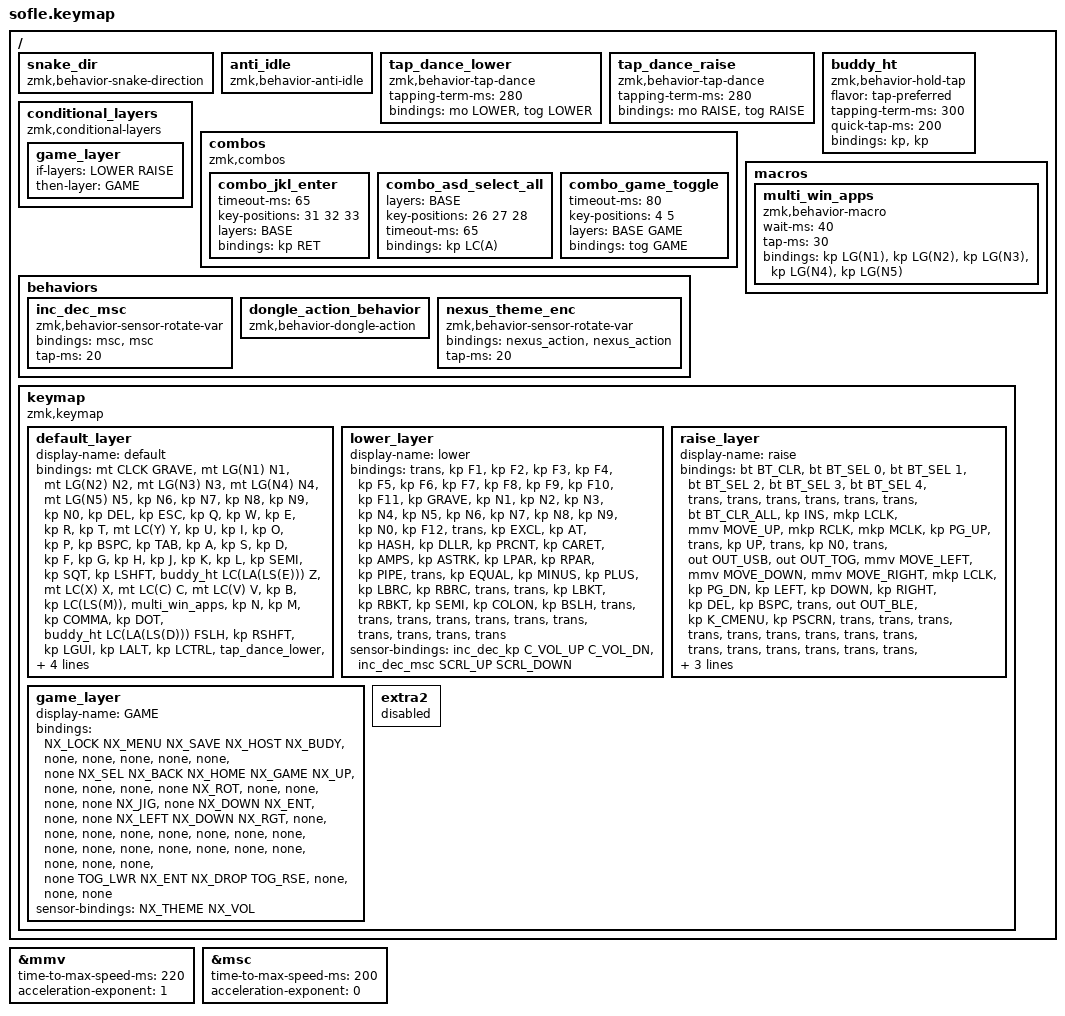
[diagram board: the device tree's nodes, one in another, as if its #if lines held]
/*
 * Copyright (c) 2020 The ZMK Contributors
 *
 * SPDX-License-Identifier: MIT
 */
#include <behaviors.dtsi>
#include <dt-bindings/zmk/keys.h>
#include <dt-bindings/zmk/bt.h>
#include <dt-bindings/zmk/rgb.h>
#include <dt-bindings/zmk/ext_power.h>
#include <dt-bindings/zmk/outputs.h>

/* --------------------------------------------------------------------------
 * Pointing defaults
 * -------------------------------------------------------------------------- */
#define ZMK_POINTING_DEFAULT_MOVE_VAL 1200
#define ZMK_POINTING_DEFAULT_SCRL_VAL 65
/* NEW: Replaced mouse.h with pointing.h for latest ZMK main branch */
#include <dt-bindings/zmk/pointing.h>

#define BASE 0
#define LOWER 1
#define RAISE 2
#define GAME 3

/ {
    /* ----------------------------------------------------------------------
     * Custom behaviors
     * ---------------------------------------------------------------------- */
    // ---------- SNAKE DIRECTION BEHAVIOR ----------
    snake_dir: snake_dir {
        compatible = "zmk,behavior-snake-direction";
        #binding-cells = <1>;
    };

    // ---------- ANTI-IDLE (HUMANIZED MOUSE JIGGLER) TOGGLE ----------
    anti_idle: anti_idle {
        compatible = "zmk,behavior-anti-idle";
        #binding-cells = <0>;
    };

    // ---------- TAP-DANCE FOR CUSTOM LAYER BEHAVIOR ----------
    tap_dance_lower: tap_dance_lower {
        compatible = "zmk,behavior-tap-dance";
        #binding-cells = <0>;
        tapping-term-ms = <280>;   // double-tap speed
        bindings = <&mo LOWER>, <&tog LOWER>;
    };

    tap_dance_raise: tap_dance_raise {
        compatible = "zmk,behavior-tap-dance";
        #binding-cells = <0>;
        tapping-term-ms = <280>;
        bindings = <&mo RAISE>, <&tog RAISE>;
    };

    // ---------- BUDDY ON HOLD: Z what's this?, / dictate ----------
    // Tap-preferred, not &mt's hold-preferred: only a real hold sends the
    // hotkey, so a fast roll like "/u" in a URL never starts Buddy talking.
    buddy_ht: buddy_ht {
        compatible = "zmk,behavior-hold-tap";
        #binding-cells = <2>;
        flavor = "tap-preferred";
        tapping-term-ms = <300>;
        quick-tap-ms = <200>;      // tap then hold = repeat the letter
        bindings = <&kp>, <&kp>;
    };

    /* Activate the GAME layer when LOWER and RAISE are both held. */
    conditional_layers {
        compatible = "zmk,conditional-layers";
        game_layer {
            if-layers = <LOWER RAISE>;
            then-layer = <GAME>;
        };
    };

    /* ----------------------------------------------------------------------
     * Combos
     * ---------------------------------------------------------------------- */
    combos {
        compatible = "zmk,combos";

        combo_jkl_enter {
            timeout-ms = <65>;          // Time window to press J+K+L together
            key-positions = <31 32 33>; // J, K, L positions in default_layer
            layers = <BASE>;            // Only active on BASE (default) layer
            bindings = <&kp RET>;       // Sends Enter
        };

        combo_asd_select_all {
            /* A + S + D on the left home row. */
            layers = <BASE>;
            key-positions = <26 27 28>;  // A, S, D 
            timeout-ms = <65>;
            bindings = <&kp LC(A)>;
        };

        combo_game_toggle {
            /*
             * 4 + 5 (left-hand number row) toggles the GAME layer, so you can
             * stay in it without holding LOWER+RAISE while you play.
             */
            timeout-ms = <80>;
            key-positions = <4 5>;  // number-row 4 + 5
            layers = <BASE GAME>;
            bindings = <&tog GAME>;
        };

    };

    /* ----------------------------------------------------------------------
     * Macros
     * ---------------------------------------------------------------------- */
    /* Launch or focus pinned Windows apps 1 through 5. */
    macros {
        multi_win_apps: multi_win_apps {
            compatible = "zmk,behavior-macro";
            #binding-cells = <0>;
            wait-ms = <40>;
            tap-ms  = <30>;
            bindings = <
                &kp LG(N1)
                &kp LG(N2)
                &kp LG(N3)
                &kp LG(N4)
                &kp LG(N5)
            >;
        };
    };

    behaviors {
        /* Scroll wheel behavior for the encoder sensor. */
        inc_dec_msc: inc_dec_msc {
            compatible = "zmk,behavior-sensor-rotate-var";
            #sensor-binding-cells = <2>;
            bindings = <&msc>, <&msc>;
            tap-ms = <20>;
        };

        // Dongle action toggle (snake <-> menu). Defined here so peripheral
        // builds compile; merges with the identical node in snake_adapter.overlay
        // on the dongle build.
        dongle_action_behavior: dongle_action_behavior {
            compatible = "zmk,behavior-dongle-action";
            #binding-cells = <0>;
        };
    };

    keymap {
        compatible = "zmk,keymap";

        default_layer {
            display-name = "default";
            /*
             * DEFAULT
             * ,-----------------------------------------------.   ,-----------------------------------------------.
             * | ` Caps | Win1 | Win2 | Win3 | Win4 | Win5     |   |  6   |  7   |  8   |  9   |  0   | Del      |
             * | Esc    |  Q   |  W   |  E   |  R   |  T       |   | C-Y  |  U   |  I   |  O   |  P   | Bksp     |
             * | Tab    |  A   |  S   |  D   |  F   |  G       |   |  H   |  J   |  K   |  L   |  ;   | '        |
             * | Shift  | Z*   | C-X  | C-C  | C-V  |  B |Teams|   | Apps |  N   |  M   |  ,   |  .   | /* |Shift|
             * `-----------------------------+------+-------'   `------+-------+-----------------------------'
             *            | Gui  | Alt  | Ctrl | Lower | Enter |   | Space | Raise | Ctrl | Alt  | Gui |
             *            `------------------------------------'   `-----------------------------------'
             *
             * Encoder pushes: left = Teams mic mute, right = multi app macro.
             * Combos: A+S+D = Ctrl+A, J+K+L = Enter, 4+5 = Snake layer toggle.
             * Z* and /*: hold and talk, then let go (the NEXUS voice window):
             *   Z* hold = "what's this?" about the selection (Ctrl+Alt+Shift+E) -
             *        the left hand, free while the right one selects
             *   /* hold = dictate anywhere (Ctrl+Alt+Shift+D)
             * Tap types as usual. Talk on and off: Ctrl+Alt+Shift+N, or the
             * window's button.
             */
            bindings = <
&mt CLCK GRAVE &mt LG(N1) N1  &mt LG(N2) N2  &mt LG(N3) N3  &mt LG(N4) N4  &mt LG(N5) N5                                        &kp N6       &kp N7    &kp N8             &kp N9    &kp N0   &kp DEL
&kp ESC        &kp Q          &kp W          &kp E          &kp R          &kp T                                                &mt LC(Y) Y  &kp U     &kp I              &kp O     &kp P    &kp BSPC
&kp TAB        &kp A          &kp S          &kp D          &kp F          &kp G                                                &kp H        &kp J     &kp K              &kp L     &kp SEMI &kp SQT
&kp LSHFT      &buddy_ht LC(LA(LS(E))) Z &mt LC(X) X &mt LC(C) C &mt LC(V) V &kp B &kp LC(LS(M))      &multi_win_apps &kp N        &kp M     &kp COMMA          &kp DOT  &buddy_ht LC(LA(LS(D))) FSLH &kp RSHFT
                              &kp LGUI       &kp LALT       &kp LCTRL      &tap_dance_lower  &kp RET            &kp SPACE   &tap_dance_raise &kp RCTRL &kp RALT           &kp RGUI
            >;

            sensor-bindings = <&inc_dec_kp C_VOL_UP C_VOL_DN &inc_dec_msc SCRL_UP SCRL_DOWN>;
        };

        lower_layer {
            display-name = "lower";
            /*
             * LOWER
             * ,-----------------------------------------------.   ,-----------------------------------------------.
             * | trans | F1   | F2   | F3   | F4   | F5        |   | F6   | F7   | F8   | F9   | F10  | F11      |
             * | `     | 1    | 2    | 3    | 4    | 5         |   | 6    | 7    | 8    | 9    | 0    | F12      |
             * | trans | !    | @    | #    | $    | %         |   | ^    | &    | *    | (    | )    | |        |
             * | trans | =    | -    | +    | {    | } |trans  |   |trans | [    | ]    | ;    | :    | \ |trans |
             * `-----------------------------+------+-------'   `------+-------+-----------------------------'
             */
            bindings = <
&trans    &kp F1    &kp F2    &kp F3      &kp F4    &kp F5                    &kp F6    &kp F7   &kp F8    &kp F9    &kp F10   &kp F11
&kp GRAVE &kp N1    &kp N2    &kp N3      &kp N4    &kp N5                    &kp N6    &kp N7   &kp N8    &kp N9    &kp N0    &kp F12
&trans    &kp EXCL  &kp AT    &kp HASH    &kp DLLR  &kp PRCNT                 &kp CARET &kp AMPS &kp ASTRK &kp LPAR  &kp RPAR  &kp PIPE
&trans    &kp EQUAL &kp MINUS &kp PLUS &kp LBRC  &kp RBRC   &trans &trans  &kp LBKT  &kp RBKT &kp SEMI  &kp COLON &kp BSLH  &trans
                    &trans    &trans      &trans    &trans     &trans &trans  &trans    &trans   &trans    &trans
            >;

            sensor-bindings = <&inc_dec_kp C_VOL_UP C_VOL_DN &inc_dec_msc SCRL_UP SCRL_DOWN>;
        };

        raise_layer {
            display-name = "raise";
            /*
             * RAISE
             * ,------------------------------------------------.   ,-----------------------------------------------.
             * | BTClr | BT1  | BT2  | BT3  | BT4  | BT5       |   | trans| trans| trans| trans| trans| trans    |
             * | BTAll | Ins  | LClk | MUp  | RClk | MClk      |   | PgUp | trans| Up   | trans| 0    | trans    |
             * | USB   | Out  | MLeft| MDown| MRight|LClk      |   | PgDn | Left | Down | Right| Del  | Bksp     |
             * | trans | BLE  | Menu | PrScr| trans|trans|trans|   |trans | trans| trans| trans| trans|trans|trans|
             * `------------------------------+------+------'    `------+-------+-----------------------------'
             */
            bindings = <
&bt BT_CLR         &bt BT_SEL 0     &bt BT_SEL 1      &bt BT_SEL 2 &bt BT_SEL 3 &bt BT_SEL 4                       &trans    &trans    &trans   &trans    &trans  &trans
&bt BT_CLR_ALL     &kp INS          &mkp LCLK         &mmv MOVE_UP     &mkp RCLK        &mkp MCLK                  &kp PG_UP &trans    &kp UP   &trans    &kp N0  &trans
&out OUT_USB       &out OUT_TOG     &mmv MOVE_LEFT    &mmv MOVE_DOWN   &mmv MOVE_RIGHT  &mkp LCLK                  &kp PG_DN &kp LEFT  &kp DOWN &kp RIGHT &kp DEL &kp BSPC
&trans             &out OUT_BLE     &kp K_CMENU       &kp PSCRN        &trans           &trans       &trans &trans &trans    &trans    &trans   &trans    &trans  &trans
                        &trans       &trans       &trans       &trans        &trans  &trans  &trans    &trans    &trans   &trans
            >;
            
            sensor-bindings = <&inc_dec_kp C_VOL_UP C_VOL_DN &inc_dec_msc SCRL_UP SCRL_DOWN>;
        };

        game_layer {
            display-name = "GAME";
            /*
             * GAME - dongle UI control layer.
             *
             * Reached by holding LOWER+RAISE, or latched with the 4+5 combo so
             * you can play without holding anything.
             *
             * These are the FALLBACK bindings, used only by a firmware built
             * WITHOUT the nexus_dongle shield. On a NEXUS build the whole
             * layer is replaced at the bottom of this file - see the
             * #ifdef NEXUS_DONGLE block for the arrangement you actually get.
             *
             * This grid is a fallback. The NEXUS build replaces the whole
             * layer at the bottom of this file (#ifdef NEXUS_DONGLE); any
             * other firmware built from this branch gets these keys.
             *
             * There are deliberately no &snake_dir bindings here. The snake
             * dongle lives on its own branch now, so carrying a second set of
             * game controls this branch never uses would just be a layer that
             * has to be kept in sync with a firmware nobody builds here.
             *
             * A still toggles anti-idle (the mouse jiggler): press once = on,
             * press again = off. It keeps running after you leave this layer.
             *
             * ,-----------------------------------------------.   ,-----------------------------------------------.
             * | none  | none | none | none | none | none      |   | none | none | none | none | none | none     |
             * | none  | none | none | none | none | none      |   | none | none | none | none | none | none     |
             * | none  |AntiI | none | none | none | none      |   | none | none | none | none | none | none     |
             * | none  | none | none | none | none | none|none |   | none | none | none | none | none |none|none |
             * `-----------------------------+------+-------'   `------+-------+-----------------------------'
             *              | none | none | none |Lower | none |   | none |Raise | none | none | none |
             */
            bindings = <
&none  &none       &none  &none  &none  &none                        &none  &none  &none  &none  &none  &none
&none  &none       &none  &none  &none  &none                        &none  &none  &none  &none  &none  &none
&none  &anti_idle  &none  &none  &none  &none                        &none  &none  &none  &none  &none  &none
&none  &none       &none  &none  &none  &none   &none        &none   &none  &none  &none  &none  &none  &none
              &none  &none  &none  &tog LOWER  &none       &none  &tog RAISE  &none  &none  &none
            >;
            sensor-bindings = <&inc_dec_kp C_VOL_UP C_VOL_DN &inc_dec_msc SCRL_UP SCRL_DOWN>;
        };

        extra2 {
            status = "reserved";
        };
    };
};

/* --------------------------------------------------------------------------
 * Mouse feel tuning
 * -------------------------------------------------------------------------- */
&mmv {
        time-to-max-speed-ms = <220>;     /* default ~300, faster ramp */
        acceleration-exponent = <1>;      /* predictable */
};

&msc {
        time-to-max-speed-ms = <200>;
        acceleration-exponent = <0>;      /* linear scroll feel */
};

/* --------------------------------------------------------------------------
 * NEXUS dongle control layer
 *
 * Compiled ONLY into the nexus_dongle build. CONFIG_NEXUS is set by the
 * nexus_dongle shield and by nothing else, so the two halves, the settings
 * reset build and the existing snake_dongle build never see any of this and
 * are byte-for-byte unaffected. That is deliberate: Section 69 says NEXUS must
 * not require redesigning a keymap that already works.
 *
 * It re-points the existing GAME layer rather than adding one, so the
 * way you reach it does not change: hold LOWER+RAISE, or the 4+5 combo.
 *
 * The physical Action button on the dongle can pause, resume, restart and exit
 * on its own, but one button cannot steer a falling tetromino - that is what
 * these bindings are for. They emit the same logical verbs the button does
 * (Section 13), so the game genuinely cannot tell a keycap from a finger.
 *
 *   I           rotate
 *   J  K  L     left, soft drop, right
 *   thumbs      hard drop
 *   top-right   select: pause / resume / restart, by context
 *   Q / W       home, game center
 *   top-left    ZMK Studio unlock (Section 32)
 * -------------------------------------------------------------------------- */
/*
 * NEXUS_DONGLE, not CONFIG_NEXUS. Zephyr builds the devicetree before it runs
 * Kconfig, so autoconf.h does not exist while this file is preprocessed and
 * any `#ifdef CONFIG_...` here is silently false - which is exactly how this
 * whole block failed to compile the first time, leaving the old &snake_dir and
 * &dongle_action_behavior bindings live on a NEXUS build.
 *
 * NEXUS_DONGLE is defined by the nexus_dongle shield overlay, which Zephyr
 * concatenates ahead of this file.
 */
#ifdef NEXUS_DONGLE

#include <dt-bindings/nexus.h>

/* Keeps the binding count identical whether or not Studio is built, so this
 * layer never has two shapes to keep in sync. */

/*
 * Short aliases so the grid below is actually a grid.
 *
 * `&nexus_action NEXUS_ACT_GAME_CENTER` is 35 characters and `&none` is 5;
 * mixing them in one table makes the columns meaningless, and a keymap you
 * cannot read by eye is a keymap with a silent typo in it. Every alias here
 * fits one cell, so a column really is a key column.
 */
/*
 * Encoder -> theme, with no menu in the way.
 *
 * zmk,behavior-sensor-rotate-var takes two phandles (clockwise,
 * counter-clockwise) and passes the two sensor params to them, so one node
 * covers both directions of one encoder.
 */
/ {
    behaviors {
        nexus_theme_enc: nexus_theme_enc {
            compatible = "zmk,behavior-sensor-rotate-var";
            #sensor-binding-cells = <2>;
            bindings = <&nexus_action>, <&nexus_action>;
            tap-ms = <20>;
        };
    };
};

#define NX_THEME &nexus_theme_enc NEXUS_ACT_THEME_NEXT NEXUS_ACT_THEME_PREV
#define NX_VOL   &inc_dec_kp C_VOL_UP C_VOL_DN

#define NX_LOCK  &studio_unlock
#define NX_MENU  &nexus_action NEXUS_ACT_MENU
#define NX_SAVE  &nexus_action NEXUS_ACT_SAVE
#define NX_HOME  &nexus_action NEXUS_ACT_HOME
#define NX_GAME  &nexus_action NEXUS_ACT_GAME_CENTER
#define NX_BACK  &nexus_action NEXUS_ACT_BACK
#define NX_UP    &nexus_action NEXUS_ACT_UP
#define NX_DOWN  &nexus_action NEXUS_ACT_DOWN
#define NX_ENT   &nexus_action NEXUS_ACT_SELECT
#define NX_SEL   &nexus_action NEXUS_ACT_SELECT
#define NX_ROT   &nexus_action NEXUS_ACT_ROTATE
#define NX_LEFT  &nexus_action NEXUS_ACT_LEFT
#define NX_RGT   &nexus_action NEXUS_ACT_RIGHT
#define NX_DROP  &nexus_action NEXUS_ACT_DROP
#define NX_HOST  &nexus_action NEXUS_ACT_HOST
#define NX_BUDY  &nexus_action NEXUS_ACT_BUDDY
#define NX_JIG   &anti_idle
#define TOG_LWR  &tog LOWER
#define TOG_RSE  &tog RAISE

&{/keymap/game_layer} {
    display-name = "GAME";
    /*
     * GAME - everything the dongle's Action button can do, plus the things
     * one button cannot.
     *
     * LEFT drives the dongle UI, RIGHT plays the game. The button has to
     * overload one gesture per screen; the keyboard does not, so navigating
     * Settings is UP / DOWN / ENTER / BACK as separate keys instead of
     * tap-to-move and hold-to-pick. SAVE has no button equivalent at all -
     * from the button you have to walk to the SAVE row - so it is bound here
     * and works from any screen.
     *
     * The verbs are context-sensitive by design (Section 13): ENTER picks a
     * settings row and pauses a game, DOWN moves the cursor and soft-drops.
     * The screen decides, not the key - which is why the same key can appear
     * on both halves without meaning two things.
     *
     * Empty keys are &none, not &trans: GAME is a conditional layer over
     * LOWER+RAISE, so &trans would type letters into whatever has focus
     * while you play. Masking is the point.
     *
     *          LEFT = dongle UI                          RIGHT = the game
     * ,------------------------------------------------.   ,------------------------------------------------.
     * |Unlock| MENU | SAVE | HOST |BUDDY | none        |   | none | none | none | none | none | PAUSE       |
     * | BACK | HOME | GAMES|  UP  | none | none        |   | none | none |ROTATE| none | none | none        |
     * | none |AntiI | none | DOWN |ENTER | none        |   | none | LEFT | DOWN | RIGHT| none | none        |
     * | none | none | none | none | none | none | none |   | none | none | none | none | none | none | none |
     * `------------------------------+------+--------'    `------+-------+------------------------------'
     *              | none | none | none |Lower |ENTER  |   | DROP |Raise | none | none | none |
     *
     *   Unlock ZMK Studio unlock     MENU  Settings      SAVE  persist settings
     *   HOME   dashboard             GAMES Game Center   BACK  leave / go up
     *   HOST   clock + companion     BUDDY Buddy's face (again: back)
     *   UP/DOWN move the cursor
     *   ENTER  pick a row, or pause a game
     *   I rotate   J/K/L left, soft drop, right   DROP hard drop
     */
    bindings = <
NX_LOCK     NX_MENU     NX_SAVE     NX_HOST     NX_BUDY     &none       &none       &none       &none       &none       &none       NX_SEL
NX_BACK     NX_HOME     NX_GAME     NX_UP       &none       &none       &none       &none       NX_ROT      &none       &none       &none
&none       NX_JIG      &none       NX_DOWN     NX_ENT      &none       &none       NX_LEFT     NX_DOWN     NX_RGT      &none       &none
&none       &none       &none       &none       &none       &none       &none       &none       &none       &none       &none       &none       &none       &none
                      &none       &none       &none       TOG_LWR     NX_ENT      NX_DROP     TOG_RSE     &none       &none       &none
    >;

    /*
     * Left encoder cycles the theme, right encoder keeps volume - still worth
     * having with a game up. The theme applies on the detent and saves itself
     * a few seconds after you stop turning, so no menu trip and no flash write
     * per click. Swap NX_VOL for a brightness pair if you would rather.
     */
    sensor-bindings = <NX_THEME NX_VOL>;
};

#endif /* NEXUS_DONGLE */
